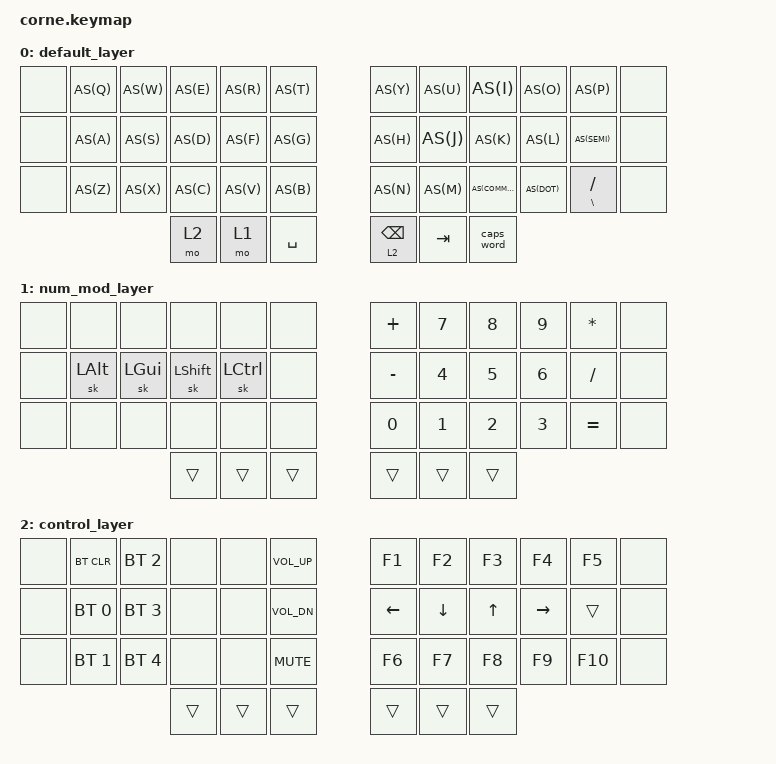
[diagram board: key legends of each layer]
/*
 * Copyright (c) 2020 The ZMK Contributors
 *
 * SPDX-License-Identifier: MIT
 */

#include <behaviors.dtsi>
#include <dt-bindings/zmk/keys.h>
#include <dt-bindings/zmk/bt.h>

#define AS(keycode) &as LS(keycode) keycode     // Autoshift Macro

&lt {
    quick_tap_ms = <200>;
};

/ {
        behaviors {
          as: auto_shift {
            compatible = "zmk,behavior-hold-tap";
            label = "AUTO_SHIFT";
            #binding-cells = <2>;
            tapping_term_ms = <175>;
            quick_tap_ms = <0>;
            flavor = "tap-preferred";
            bindings = <&kp>, <&kp>;
          };
        };
        combos {
          compatible = "zmk,combos";
          combo_delete {
            timeout-ms = <50>;
            key-positions = <14 15>;
            bindings = <&kp BKSP>;
          };
          combo_esc {
            timeout-ms = <50>;
            key-positions = <15 16>;
            bindings = <&kp ESC>;
          };
          combo_enter {
            timeout-ms = <50>;
            key-positions = <19 20>;
            bindings = <&kp ENTER>;
            layers = <0>;
          };
          combo_tab {
            timeout-ms = <50>;
            key-positions = <20 21>;
            bindings = <&kp TAB>;
          };
          combo_l_paren {
            timeout-ms = <50>;
            key-positions = <16 17>;
            bindings = <&kp LPAR>;
          };
          combo_l_brace {
            timeout-ms = <50>;
            key-positions = <4 16>;
            bindings = <&kp LBRC>;
          };
          combo_l_bracket {
            timeout-ms = <50>;
            key-positions = <16 28>;
            bindings = <&kp LBKT>;
          };
          combo_r_paren {
            timeout-ms = <50>;
            key-positions = <18 19>;
            bindings = <&kp RPAR>;
          };
          combo_r_brace {
            timeout-ms = <50>;
            key-positions = <7 19>;
            bindings = <&kp RBRC>;
          };
          combo_r_bracket {
            timeout-ms = <50>;
            key-positions = <19 31>;
            bindings = <&kp RBKT>;
          };
          combo_or {
            timeout-ms = <50>;
            key-positions = <1 13>;
            bindings = <&kp PIPE>;
          };
          combo_and {
            timeout-ms = <50>;
            key-positions = <2 14>;
            bindings = <&kp AMPS>;
          };
          combo_exclamation {
            timeout-ms = <50>;
            key-positions = <3 15>;
            bindings = <&kp EXCL>;
          };
          combo_equal {
            timeout-ms = <50>;
            key-positions = <5 17>;
            bindings = <&kp EQUAL>;
          };
          combo_question {
            timeout-ms = <50>;
            key-positions = <17 29>;
            bindings = <&kp QMARK>;
          };
          combo_single_quote {
            timeout-ms = <50>;
            key-positions = <20 32>;
             bindings = <&kp SQT>;
          };
          combo_double_quote {
            timeout-ms = <50>;
            key-positions = <21 33>;
             bindings = <&kp DQT>;
          };
          combo_backtick {
            timeout-ms = <50>;
            key-positions = <22 34>;
             bindings = <&kp GRAVE>;
          };
          combo_tilde {
            timeout-ms = <50>;
            key-positions = <13 25>;
            bindings = <&kp TILDE>;
          };
          combo_under {
            timeout-ms = <50>;
            key-positions = <14 26>;
            bindings = <&kp UNDER>;
          };
          combo_caret {
            timeout-ms = <50>;
            key-positions = <15 27>;
            bindings = <&kp CARET>;
          };
          combo_at {
            timeout-ms = <50>;
            key-positions = <6 18>;
            bindings = <&kp AT>;
          };
          combo_pound {
            timeout-ms = <50>;
            key-positions = <8 20>;
            bindings = <&kp POUND>;
          };
          combo_dollar {
            timeout-ms = <50>;
            key-positions = <9 21>;
            bindings = <&kp DLLR>;
          };
          combo_percent {
            timeout-ms = <50>;
            key-positions = <10 22>;
            bindings = <&kp PRCNT>;
          };
          combo-dash {
            timeout-ms = <50>;
            key-positions = <18 30>;
             bindings = <&kp MINUS>;
          };
        };
        keymap {
                compatible = "zmk,keymap";

                default_layer {
// -----------------------------------------------------------------------------------------
// |      |  Q  |  W  |  E  |  R  |  T  |   |  Y     |  U  |  I  |  O  |  P  |      |
// |      |  A  |  S  |  D  |  F  |  G  |   |  H     |  J  |  K  |  L  | ;/: |      |
// |      |  Z  |  X  |  C  |  V  |  B  |   |  N     |  M  |  ,  |  .  |  /  |      |
//                    |     | TAB | SPC |   | BKSP/L2| L1  |     |
                        bindings = <
   &none AS(Q) AS(W) AS(E) AS(R) AS(T)   AS(Y) AS(U)  AS(I)     AS(O)   AS(P)     &none
   &none AS(A) AS(S) AS(D) AS(F) AS(G)   AS(H) AS(J)  AS(K)     AS(L)   AS(SEMI)  &none
   &none AS(Z) AS(X) AS(C) AS(V) AS(B)   AS(N) AS(M)  AS(COMMA) AS(DOT) &mt BSLH FSLH  &none
               &mo 2 &mo 1 &kp SPACE   &lt 2 BKSP &kp TAB &caps_word
                        >;
                };
                num_mod_layer {
// -----------------------------------------------------------------------------------------
// |      |     |     |     |     |     |   |  +  |  7  |  8  |  9  |  *  |      |
// |      | ALT | GUI | SHFT| CTRL|     |   |  -  |  4  |  5  |  6  |  /  |      |
// |      |     |     |     |     |     |   |  0  |  1  |  2  |  3  |  =  |      |
//                    |     |     |     |   |     |     |     |
                        bindings = <
   &none  &none     &none     &none      &none     &none      &kp PLUS  &kp N7  &kp N8  &kp N9   &kp STAR   &none
   &none  &sk LALT  &sk LGUI  &sk LSHIFT &sk LCTRL &none      &kp MINUS &kp N4  &kp N5  &kp N6   &kp FSLH   &none 
   &none  &none     &none     &none      &none     &none      &kp N0    &kp N1  &kp N2  &kp N3   &kp EQUAL  &none
                              &trans     &trans    &trans     &trans    &trans  &trans  
                        >;
                };
                control_layer {
// -----------------------------------------------------------------------------------------
// |      |BTCLR| BT3 |     |     |VOLUP|   | F1  | F2  | F3  | F4  | F5  |      |
// |      | BT1 | BT4 |     |     |VOLDN|   | LFT | DWN | UP  | RGHT|     |      |
// |      | BT2 | BT5 |     |     |MUTE |   | F6  | F7  | F8  | F9  | F10 |      |
//                    |     |     |     |   |     |     |     |
                        bindings = <
   &none   &bt BT_CLR    &bt BT_SEL 2  &none    &none  &kp K_VOL_UP     &kp F1   &kp F2    &kp F3  &kp F4     &kp F5   &none
   &none   &bt BT_SEL 0  &bt BT_SEL 3  &none    &none  &kp K_VOL_DN     &kp LEFT &kp DOWN  &kp UP  &kp RIGHT  &trans   &none
   &none   &bt BT_SEL 1  &bt BT_SEL 4  &none    &none  &kp K_MUTE       &kp F6   &kp F7    &kp F8  &kp F9     &kp F10  &none
                                           &trans   &trans  &trans      &trans   &trans    &trans
                        >;
                };
        };
};
